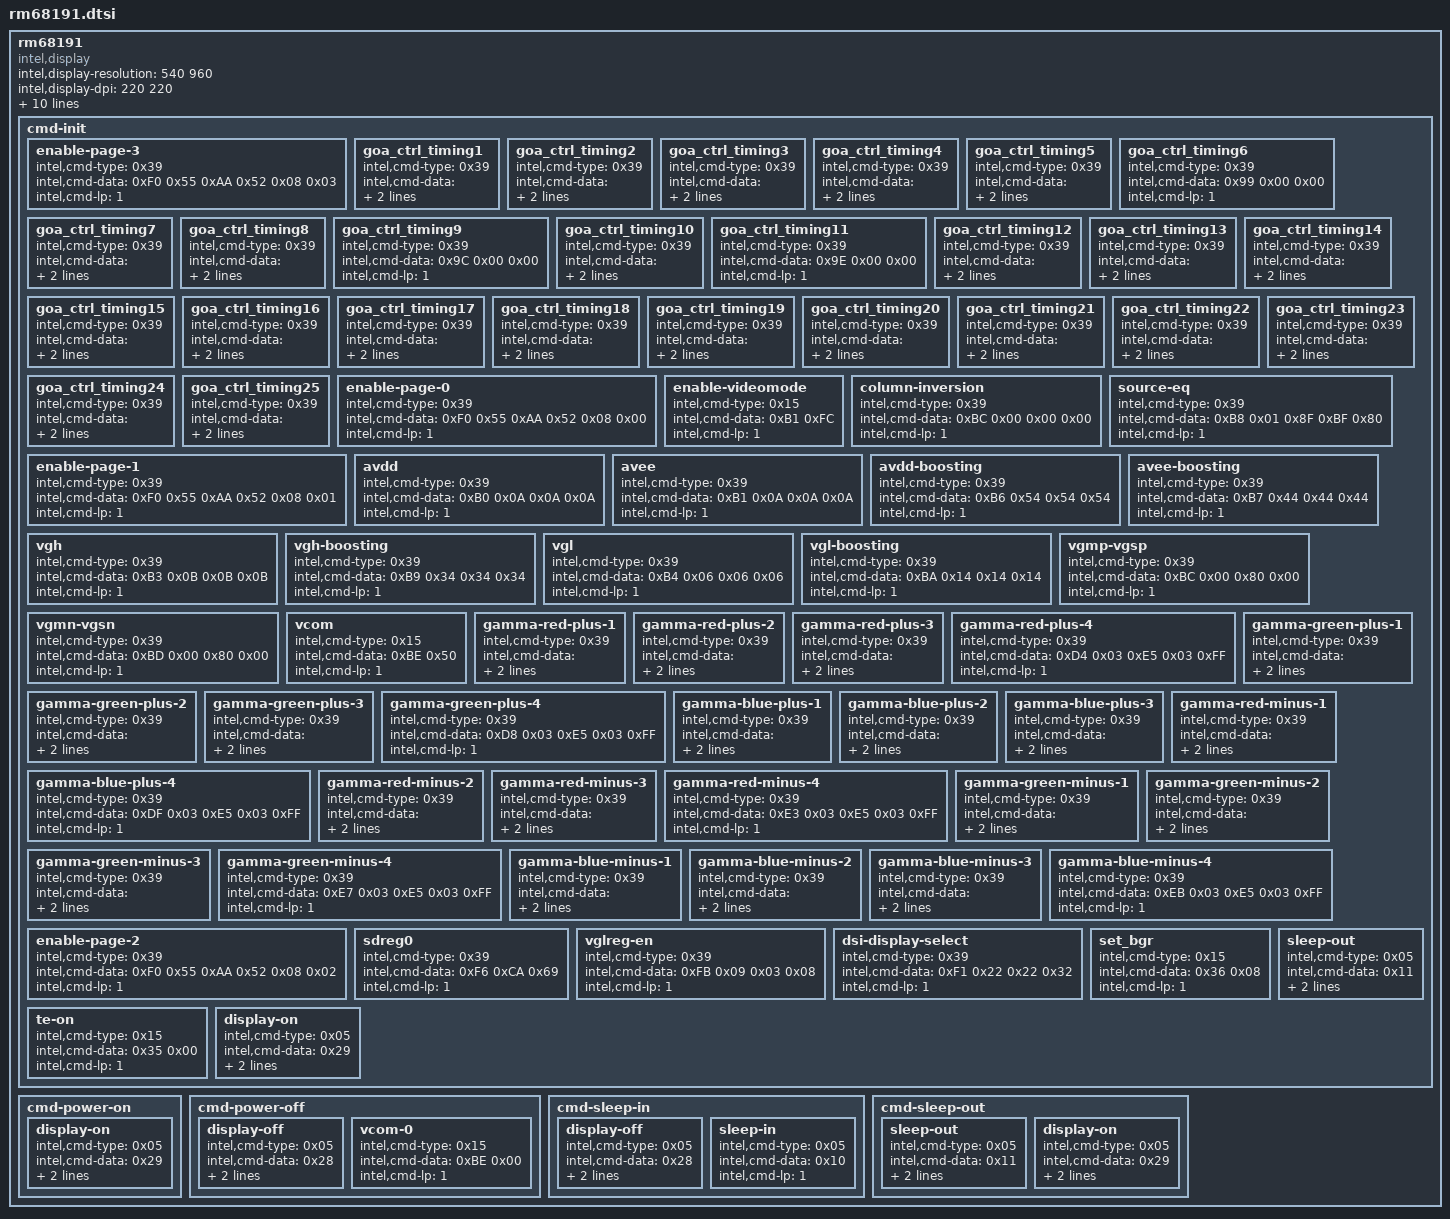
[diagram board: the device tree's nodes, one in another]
	rm68191 {
		compatible = "intel,display";
		intel,display-resolution= <540 960>;
		intel,display-dpi= <220 220>;

		/* MIPI-DSI video mode settings */
		intel,display-vid-hfp-hs-bytes = <32>;
		intel,display-vid-hbp-hs-bytes = <32>;
		intel,display-vid-hsa-hs-bytes = <8>;
		intel,display-vid-vfp-lines = <12>;
		intel,display-vid-vbp-lines = <12>;
		intel,display-vid-vsa-lines = <4>;

		intel,display-vid-mode = "burst";
		intel,display-vid-id = <0>;
		intel,display-vid-pixel = "24packed";

		intel,display-reset = <1 1 0 5 1 50>;

		cmd-init {
			enable-page-3 {
				intel,cmd-type = <0x39>;
				intel,cmd-data = <0xF0 0x55 0xAA 0x52 0x08 0x03>;
				intel,cmd-lp = <1>;
			};
			goa_ctrl_timing1 {
				intel,cmd-type = <0x39>;
				intel,cmd-data = <0x90 0x05 0x14 0x05 0x00 0x00 0x00 0x8C 0x00 0x00>;
				intel,cmd-lp = <1>;
			};
			goa_ctrl_timing2 {
				intel,cmd-type = <0x39>;
				intel,cmd-data = <0x91 0x05 0x14 0x00 0x00 0x00 0x00 0x8C 0x00 0x00>;
				intel,cmd-lp = <1>;
			};
			goa_ctrl_timing3 {
				intel,cmd-type = <0x39>;
				intel,cmd-data = <0x92 0x40 0x09 0x0A 0x0B 0x0C 0x00 0xFF 0x00 0x00 0x05 0x08>;
				intel,cmd-lp = <1>;
			};
			goa_ctrl_timing4 {
				intel,cmd-type = <0x39>;
				intel,cmd-data = <0x94 0x00 0x08 0x05 0x03 0xCE 0x03 0xD0 0x0C>;
				intel,cmd-lp = <1>;
			};
			goa_ctrl_timing5 {
				intel,cmd-type = <0x39>;
				intel,cmd-data = <0x95 0x40 0x0D 0x00 0x0E 0x00 0x0F 0x00 0x10 0x00 0xFF 0x00 0x00 0x00 0x05 0x00 0x08>;
				intel,cmd-lp = <1>;
			};
			goa_ctrl_timing6 {
				intel,cmd-type = <0x39>;
				intel,cmd-data = <0x99 0x00 0x00>;
				intel,cmd-lp = <1>;
			};
			goa_ctrl_timing7 {
				intel,cmd-type = <0x39>;
				intel,cmd-data = <0x9A 0x80 0x0D 0x03 0xD2 0x03 0xD4 0x00 0x00 0x00 0x00 0x50>;
				intel,cmd-lp = <1>;
			};
			goa_ctrl_timing8 {
				intel,cmd-type = <0x39>;
				intel,cmd-data = <0x9B 0x00 0x00 0x00 0x00 0x00 0x00>;
				intel,cmd-lp = <1>;
			};
			goa_ctrl_timing9 {
				intel,cmd-type = <0x39>;
				intel,cmd-data = <0x9C 0x00 0x00>;
				intel,cmd-lp = <1>;
			};
			goa_ctrl_timing10 {
				intel,cmd-type = <0x39>;
				intel,cmd-data = <0x9D 0x01 0x01 0x01 0x01 0x01 0x01 0x00 0x00>;
				intel,cmd-lp = <1>;
			};
			goa_ctrl_timing11 {
				intel,cmd-type = <0x39>;
				intel,cmd-data = <0x9E 0x00 0x00>;
				intel,cmd-lp = <1>;
			};
			goa_ctrl_timing12 {
				intel,cmd-type = <0x39>;
				intel,cmd-data = <0xA0 0x95 0x14 0x1F 0x1F 0x1F 0x1F 0x1F 0x1F 0x0B 0x1F>;
				intel,cmd-lp = <1>;
			};
			goa_ctrl_timing13 {
				intel,cmd-type = <0x39>;
				intel,cmd-data = <0xA1 0x1F 0x1F 0x09 0x1F 0x1F 0x1F 0x0F 0x1F 0x1F 0x1F>;
				intel,cmd-lp = <1>;
			};
			goa_ctrl_timing14 {
				intel,cmd-type = <0x39>;
				intel,cmd-data = <0xA2 0x0D 0x1F 0x01 0x1F 0x03 0x1F 0x1F 0x1F 0x05 0x1F>;
				intel,cmd-lp = <1>;
			};
			goa_ctrl_timing15 {
				intel,cmd-type = <0x39>;
				intel,cmd-data = <0xA3 0x1F 0x1F 0x1F 0x1F 0x1F 0x1F 0x1F 0x1F 0x1F 0x1F>;
				intel,cmd-lp = <1>;
			};
			goa_ctrl_timing16 {
				intel,cmd-type = <0x39>;
				intel,cmd-data = <0xA4 0x1F 0x04 0x1F 0x1F 0x1F 0x02 0x1F 0x00 0x1F 0x0C>;
				intel,cmd-lp = <1>;
			};
			goa_ctrl_timing17 {
				intel,cmd-type = <0x39>;
				intel,cmd-data = <0xA5 0x1F 0x1F 0x1F 0x0E 0x1F 0x1F 0x1F 0x08 0x1F 0x1F>;
				intel,cmd-lp = <1>;
			};
			goa_ctrl_timing18 {
				intel,cmd-type = <0x39>;
				intel,cmd-data = <0xA6 0x1F 0x0A 0x1F 0x1F 0x1F 0x1F 0x1F 0x1F 0x14 0x15>;
				intel,cmd-lp = <1>;
			};
			goa_ctrl_timing19 {
				intel,cmd-type = <0x39>;
				intel,cmd-data = <0xA7 0x14 0x15 0x1F 0x1F 0x1F 0x1F 0x1F 0x1F 0x0C 0x1F>;
				intel,cmd-lp = <1>;
			};
			goa_ctrl_timing20 {
				intel,cmd-type = <0x39>;
				intel,cmd-data = <0xA8 0x1F 0x1F 0x0E 0x1F 0x1F 0x1F 0x08 0x1F 0x1F 0x1F>;
				intel,cmd-lp = <1>;
			};
			goa_ctrl_timing21 {
				intel,cmd-type = <0x39>;
				intel,cmd-data = <0xA9 0x0A 0x1F 0x02 0x1F 0x00 0x1F 0x1F 0x1F 0x1F 0x04>;
				intel,cmd-lp = <1>;
			};
			goa_ctrl_timing22 {
				intel,cmd-type = <0x39>;
				intel,cmd-data = <0xAA 0x1F 0x1F 0x1F 0x1F 0x1F 0x1F 0x1F 0x1F 0x1F 0x1F>;
				intel,cmd-lp = <1>;
			};
			goa_ctrl_timing23 {
				intel,cmd-type = <0x39>;
				intel,cmd-data = <0xAB 0x1F 0x05 0x1F 0x1F 0x1F 0x01 0x1F 0x03 0x1F 0x0B>;
				intel,cmd-lp = <1>;
			};
			goa_ctrl_timing24 {
				intel,cmd-type = <0x39>;
				intel,cmd-data = <0xAC 0x1F 0x1F 0x1F 0x09 0x1F 0x1F 0x1F 0x0F 0x1F 0x1F>;
				intel,cmd-lp = <1>;
			};
			goa_ctrl_timing25 {
				intel,cmd-type = <0x39>;
				intel,cmd-data = <0xAD 0x1F 0x0D 0x1F 0x1F 0x1F 0x1F 0x1F 0x1F 0x15 0x14>;
				intel,cmd-lp = <1>;
			};
			enable-page-0 {
				intel,cmd-type = <0x39>;
				intel,cmd-data = <0xF0 0x55 0xAA 0x52 0x08 0x00>;
				intel,cmd-lp = <1>;
			};
			enable-videomode {
				intel,cmd-type = <0x15>;
				intel,cmd-data = <0xB1 0xFC>;
				intel,cmd-lp = <1>;
			};
			column-inversion {
				intel,cmd-type = <0x39>;
				intel,cmd-data = <0xBC 0x00 0x00 0x00>;
				intel,cmd-lp = <1>;
			};
			source-eq {
				intel,cmd-type = <0x39>;
				intel,cmd-data = <0xB8 0x01 0x8F 0xBF 0x80>;
				intel,cmd-lp = <1>;
			};
			enable-page-1 {
				intel,cmd-type = <0x39>;
				intel,cmd-data = <0xF0 0x55 0xAA 0x52 0x08 0x01>;
				intel,cmd-lp = <1>;
			};
			avdd {
				intel,cmd-type = <0x39>;
				intel,cmd-data = <0xB0 0x0A 0x0A 0x0A>;
				intel,cmd-lp = <1>;
			};
			avee {
				intel,cmd-type = <0x39>;
				intel,cmd-data = <0xB1 0x0A 0x0A 0x0A>;
				intel,cmd-lp = <1>;
			};
			avdd-boosting {
				intel,cmd-type = <0x39>;
				intel,cmd-data = <0xB6 0x54 0x54 0x54>;
				intel,cmd-lp = <1>;
			};
			avee-boosting {
				intel,cmd-type = <0x39>;
				intel,cmd-data = <0xB7 0x44 0x44 0x44>;
				intel,cmd-lp = <1>;
			};
			vgh {
				intel,cmd-type = <0x39>;
				intel,cmd-data = <0xB3 0x0B 0x0B 0x0B>;
				intel,cmd-lp = <1>;
			};
			vgh-boosting {
				intel,cmd-type = <0x39>;
				intel,cmd-data = <0xB9 0x34 0x34 0x34>;
				intel,cmd-lp = <1>;
			};
			vgl {
				intel,cmd-type = <0x39>;
				intel,cmd-data = <0xB4 0x06 0x06 0x06>;
				intel,cmd-lp = <1>;
			};
			vgl-boosting {
				intel,cmd-type = <0x39>;
				intel,cmd-data = <0xBA 0x14 0x14 0x14>;
				intel,cmd-lp = <1>;
			};
			vgmp-vgsp {
				intel,cmd-type = <0x39>;
				intel,cmd-data = <0xBC 0x00 0x80 0x00>;
				intel,cmd-lp = <1>;
			};
			vgmn-vgsn {
				intel,cmd-type = <0x39>;
				intel,cmd-data = <0xBD 0x00 0x80 0x00>;
				intel,cmd-lp = <1>;
			};
			vcom {
				intel,cmd-type = <0x15>;
				intel,cmd-data = <0xBE 0x50>;
				intel,cmd-lp = <1>;
			};
			gamma-red-plus-1 {
				intel,cmd-type = <0x39>;
				intel,cmd-data = <0xD1 0x00 0x01 0x00 0x29 0x00 0x59 0x00 0x7A 0x00 0x98 0x00 0xC3 0x00 0xE5 0x01 0x1C>;
				intel,cmd-lp = <1>;
			};
			gamma-red-plus-2 {
				intel,cmd-type = <0x39>;
				intel,cmd-data = <0xD2 0x01 0x46 0x01 0x8A 0x01 0xBD 0x02 0x0C 0x02 0x4B 0x02 0x4D 0x02 0x85 0x02 0xC0>;
				intel,cmd-lp = <1>;
			};
			gamma-red-plus-3 {
				intel,cmd-type = <0x39>;
				intel,cmd-data = <0xD3 0x02 0xE3 0x03 0x12 0x03 0x30 0x03 0x57 0x03 0x71 0x03 0x92 0x03 0xA5 0x03 0xC3>;
				intel,cmd-lp = <1>;
			};
			gamma-red-plus-4 {
				intel,cmd-type = <0x39>;
				intel,cmd-data = <0xD4 0x03 0xE5 0x03 0xFF>;
				intel,cmd-lp = <1>;
			};
			gamma-green-plus-1 {
				intel,cmd-type = <0x39>;
				intel,cmd-data = <0xD5 0x00 0x01 0x00 0x29 0x00 0x59 0x00 0x7A 0x00 0x98 0x00 0xC3 0x00 0xE5 0x01 0x1C>;
				intel,cmd-lp = <1>;
			};
			gamma-green-plus-2 {
				intel,cmd-type = <0x39>;
				intel,cmd-data = <0xD6 0x01 0x46 0x01 0x8A 0x01 0xBD 0x02 0x0C 0x02 0x4B 0x02 0x4D 0x02 0x85 0x02 0xC0>;
				intel,cmd-lp = <1>;
			};
			gamma-green-plus-3 {
				intel,cmd-type = <0x39>;
				intel,cmd-data = <0xD7 0x02 0xE3 0x03 0x12 0x03 0x30 0x03 0x57 0x03 0x71 0x03 0x92 0x03 0xA5 0x03 0xC3>;
				intel,cmd-lp = <1>;
			};
			gamma-green-plus-4 {
				intel,cmd-type = <0x39>;
				intel,cmd-data = <0xD8 0x03 0xE5 0x03 0xFF>;
				intel,cmd-lp = <1>;
			};
			gamma-blue-plus-1 {
				intel,cmd-type = <0x39>;
				intel,cmd-data = <0xD9 0x00 0x01 0x00 0x29 0x00 0x59 0x00 0x7A 0x00 0x98 0x00 0xC3 0x00 0xE5 0x01 0x1C>;
				intel,cmd-lp = <1>;
			};
			gamma-blue-plus-2 {
				intel,cmd-type = <0x39>;
				intel,cmd-data = <0xDD 0x01 0x46 0x01 0x8A 0x01 0xBD 0x02 0x0C 0x02 0x4B 0x02 0x4D 0x02 0x85 0x02 0xC0>;
				intel,cmd-lp = <1>;
			};
			gamma-blue-plus-3 {
				intel,cmd-type = <0x39>;
				intel,cmd-data = <0xDE 0x02 0xE3 0x03 0x12 0x03 0x30 0x03 0x57 0x03 0x71 0x03 0x92 0x03 0xA5 0x03 0xC3>;
				intel,cmd-lp = <1>;
			};
			gamma-blue-plus-4 {
				intel,cmd-type = <0x39>;
				intel,cmd-data = <0xDF 0x03 0xE5 0x03 0xFF>;
				intel,cmd-lp = <1>;
			};
			gamma-red-minus-1 {
				intel,cmd-type = <0x39>;
				intel,cmd-data = <0xE0 0x00 0x01 0x00 0x29 0x00 0x59 0x00 0x7A 0x00 0x98 0x00 0xC3 0x00 0xE5 0x01 0x1C>;
				intel,cmd-lp = <1>;
			};
			gamma-red-minus-2 {
				intel,cmd-type = <0x39>;
				intel,cmd-data = <0xE1 0x01 0x46 0x01 0x8A 0x01 0xBD 0x02 0x0C 0x02 0x4B 0x02 0x4D 0x02 0x85 0x02 0xC0>;
				intel,cmd-lp = <1>;
			};
			gamma-red-minus-3 {
				intel,cmd-type = <0x39>;
				intel,cmd-data = <0xE2 0x02 0xE3 0x03 0x12 0x03 0x30 0x03 0x57 0x03 0x71 0x03 0x92 0x03 0xA5 0x03 0xC3>;
				intel,cmd-lp = <1>;
			};
			gamma-red-minus-4 {
				intel,cmd-type = <0x39>;
				intel,cmd-data = <0xE3 0x03 0xE5 0x03 0xFF>;
				intel,cmd-lp = <1>;
			};
			gamma-green-minus-1 {
				intel,cmd-type = <0x39>;
				intel,cmd-data = <0xE4 0x00 0x01 0x00 0x29 0x00 0x59 0x00 0x7A 0x00 0x98 0x00 0xC3 0x00 0xE5 0x01 0x1C>;
				intel,cmd-lp = <1>;
			};
			gamma-green-minus-2 {
				intel,cmd-type = <0x39>;
				intel,cmd-data = <0xE5 0x01 0x46 0x01 0x8A 0x01 0xBD 0x02 0x0C 0x02 0x4B 0x02 0x4D 0x02 0x85 0x02 0xC0>;
				intel,cmd-lp = <1>;
			};
			gamma-green-minus-3 {
				intel,cmd-type = <0x39>;
				intel,cmd-data = <0xE6 0x02 0xE3 0x03 0x12 0x03 0x30 0x03 0x57 0x03 0x71 0x03 0x92 0x03 0xA5 0x03 0xC3>;
				intel,cmd-lp = <1>;
			};
			gamma-green-minus-4 {
				intel,cmd-type = <0x39>;
				intel,cmd-data = <0xE7 0x03 0xE5 0x03 0xFF>;
				intel,cmd-lp = <1>;
			};
			gamma-blue-minus-1 {
				intel,cmd-type = <0x39>;
				intel,cmd-data = <0xE8 0x00 0x01 0x00 0x29 0x00 0x59 0x00 0x7A 0x00 0x98 0x00 0xC3 0x00 0xE5 0x01 0x1C>;
				intel,cmd-lp = <1>;
			};
			gamma-blue-minus-2 {
				intel,cmd-type = <0x39>;
				intel,cmd-data = <0xE9 0x01 0x46 0x01 0x8A 0x01 0xBD 0x02 0x0C 0x02 0x4B 0x02 0x4D 0x02 0x85 0x02 0xC0>;
				intel,cmd-lp = <1>;
			};
			gamma-blue-minus-3 {
				intel,cmd-type = <0x39>;
				intel,cmd-data = <0xEA 0x02 0xE3 0x03 0x12 0x03 0x30 0x03 0x57 0x03 0x71 0x03 0x92 0x03 0xA5 0x03 0xC3>;
				intel,cmd-lp = <1>;
			};
			gamma-blue-minus-4 {
				intel,cmd-type = <0x39>;
				intel,cmd-data = <0xEB 0x03 0xE5 0x03 0xFF>;
				intel,cmd-lp = <1>;
			};
			enable-page-2 {
				intel,cmd-type = <0x39>;
				intel,cmd-data = <0xF0 0x55 0xAA 0x52 0x08 0x02>;
				intel,cmd-lp = <1>;
			};
			sdreg0 {
				intel,cmd-type = <0x39>;
				intel,cmd-data = <0xF6 0xCA 0x69>;
				intel,cmd-lp = <1>;
			};
			vglreg-en {
				intel,cmd-type = <0x39>;
				intel,cmd-data = <0xFB 0x09 0x03 0x08>;
				intel,cmd-lp = <1>;
			};
			dsi-display-select {
				intel,cmd-type = <0x39>;
				intel,cmd-data = <0xF1 0x22 0x22 0x32>;
				intel,cmd-lp = <1>;
			};
			set_bgr {
				intel,cmd-type = <0x15>;
				intel,cmd-data = <0x36 0x08>;
				intel,cmd-lp = <1>;
			};
			te-on {
				intel,cmd-type = <0x15>;
				intel,cmd-data = <0x35 0x00>;
				intel,cmd-lp = <1>;
			};
			sleep-out {
				intel,cmd-type = <0x05>;
				intel,cmd-data = <0x11>;
				intel,cmd-lp = <1>;
				intel,cmd-delay = <120>;
			};
			display-on{
				intel,cmd-type = <0x05>;
				intel,cmd-data = <0x29>;
				intel,cmd-lp = <1>;
				intel,cmd-delay = <100>;
			};
		};

		cmd-power-on {
			display-on{
				intel,cmd-type = <0x05>;
				intel,cmd-data = <0x29>;
				intel,cmd-lp = <1>;
				intel,cmd-delay = <100>;
			};
		};

		cmd-power-off {
			display-off{
				intel,cmd-type = <0x05>;
				intel,cmd-data = <0x28>;
				intel,cmd-lp = <1>;
				intel,cmd-delay = <50>;
			};
			vcom-0 {
				intel,cmd-type = <0x15>;
				intel,cmd-data = <0xBE 0x00>;
				intel,cmd-lp = <1>;
			};
		};

		cmd-sleep-in {
			display-off{
				intel,cmd-type = <0x05>;
				intel,cmd-data = <0x28>;
				intel,cmd-lp = <1>;
				intel,cmd-delay = <100>;
			};
			sleep-in{
				intel,cmd-type = <0x05>;
				intel,cmd-data = <0x10>;
				intel,cmd-lp = <1>;
			};
		};

		cmd-sleep-out {
			sleep-out{
				intel,cmd-type = <0x05>;
				intel,cmd-data = <0x11>;
				intel,cmd-lp = <1>;
				intel,cmd-delay = <120>;
			};
			display-on{
				intel,cmd-type = <0x05>;
				intel,cmd-data = <0x29>;
				intel,cmd-lp = <1>;
				intel,cmd-delay = <100>;
			};
		};
	};
